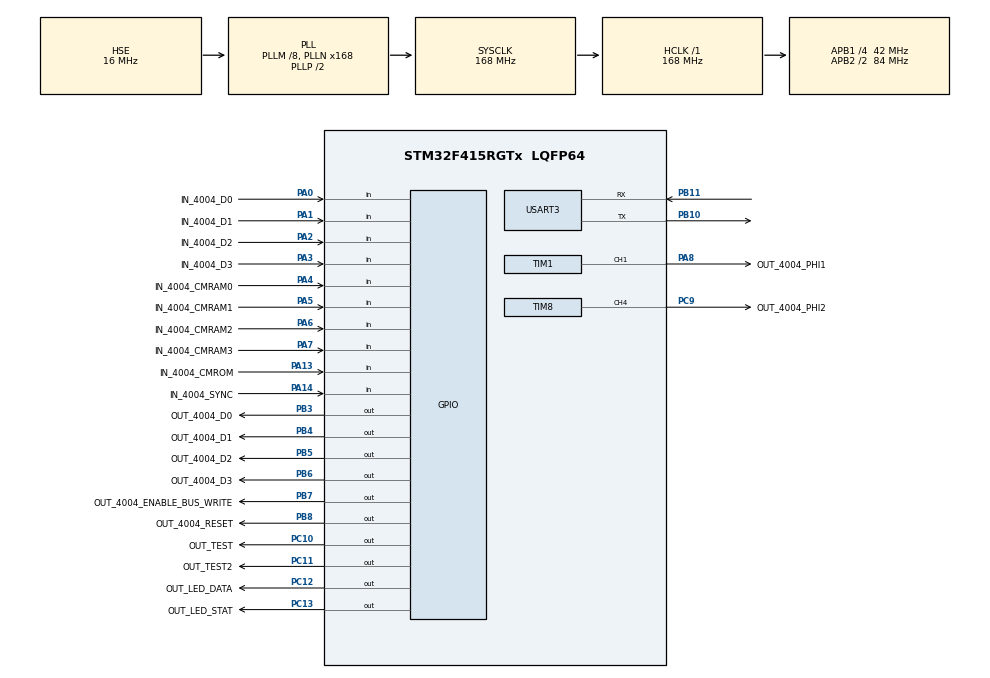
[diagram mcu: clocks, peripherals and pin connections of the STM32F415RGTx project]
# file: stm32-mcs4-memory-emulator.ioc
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Mcu.Family=STM32F4
Mcu.Name=STM32F415RGTx
Mcu.Package=LQFP64
NVIC.PriorityGroup=NVIC_PRIORITYGROUP_4
NVIC.TIM1_CC_IRQn=true\:0\:0\:false\:false\:true\:true\:true
NVIC.TIM8_CC_IRQn=true\:0\:0\:false\:false\:true\:true\:true
NVIC.USART3_IRQn=true\:0\:0\:false\:false\:true\:true\:true
PA0-WKUP.GPIO_Label=IN_4004_D0
PA0-WKUP.Signal=GPIO_Input
PA1.GPIO_Label=IN_4004_D1
PA1.Signal=GPIO_Input
PA13.GPIO_Label=IN_4004_CMROM
PA13.Signal=GPIO_Input
PA14.GPIO_Label=IN_4004_SYNC
PA14.Signal=GPIO_Input
PA2.GPIO_Label=IN_4004_D2
PA2.Signal=GPIO_Input
PA3.GPIO_Label=IN_4004_D3
PA3.Signal=GPIO_Input
PA4.GPIO_Label=IN_4004_CMRAM0
PA4.Signal=GPIO_Input
PA5.GPIO_Label=IN_4004_CMRAM1
PA5.Signal=GPIO_Input
PA6.GPIO_Label=IN_4004_CMRAM2
PA6.Signal=GPIO_Input
PA7.GPIO_Label=IN_4004_CMRAM3
PA7.Signal=GPIO_Input
PA8.GPIO_Label=OUT_4004_PHI1
PA8.Signal=S_TIM1_CH1
PB10.Mode=Asynchronous
PB10.Signal=USART3_TX
PB11.Mode=Asynchronous
PB11.Signal=USART3_RX
PB13.Signal=USART3_CTS
PB14.Signal=USART3_RTS
PB3.GPIO_Label=OUT_4004_D0
PB3.GPIO_Speed=GPIO_SPEED_FREQ_VERY_HIGH
PB3.Signal=GPIO_Output
PB4.GPIO_Label=OUT_4004_D1
PB4.GPIO_Speed=GPIO_SPEED_FREQ_VERY_HIGH
PB4.Signal=GPIO_Output
PB5.GPIO_Label=OUT_4004_D2
PB5.GPIO_Speed=GPIO_SPEED_FREQ_VERY_HIGH
PB5.Signal=GPIO_Output
PB6.GPIO_Label=OUT_4004_D3
PB6.GPIO_Speed=GPIO_SPEED_FREQ_VERY_HIGH
PB6.Signal=GPIO_Output
PB7.GPIO_Label=OUT_4004_ENABLE_BUS_WRITE
PB7.GPIO_Speed=GPIO_SPEED_FREQ_VERY_HIGH
PB7.Signal=GPIO_Output
PB8.GPIO_Label=OUT_4004_RESET
PB8.Signal=GPIO_Output
PC10.GPIO_Label=OUT_TEST
PC10.GPIO_Speed=GPIO_SPEED_FREQ_VERY_HIGH
PC10.Signal=GPIO_Output
PC11.GPIO_Label=OUT_TEST2
PC11.GPIO_Speed=GPIO_SPEED_FREQ_VERY_HIGH
PC11.Signal=GPIO_Output
PC12.GPIO_Label=OUT_LED_DATA
PC12.Signal=GPIO_Output
PC13-ANTI_TAMP.GPIO_Label=OUT_LED_STAT
PC13-ANTI_TAMP.Signal=GPIO_Output
PC9.GPIO_Label=OUT_4004_PHI2
PC9.Signal=S_TIM8_CH4
PH0-OSC_IN.Mode=HSE-External-Oscillator
PH0-OSC_IN.Signal=RCC_OSC_IN
PH1-OSC_OUT.Mode=HSE-External-Oscillator
PH1-OSC_OUT.Signal=RCC_OSC_OUT
ProjectManager.HeapSize=0x200
ProjectManager.StackSize=0x400
ProjectManager.TargetToolchain=SW4STM32
RCC.48MHZClocksFreq_Value=48000000
RCC.AHBFreq_Value=168000000
RCC.APB1CLKDivider=RCC_HCLK_DIV4
RCC.APB1Freq_Value=42000000
RCC.APB1TimFreq_Value=84000000
RCC.APB2CLKDivider=RCC_HCLK_DIV2
RCC.APB2Freq_Value=84000000
RCC.APB2TimFreq_Value=168000000
RCC.CortexFreq_Value=168000000
RCC.HCLKFreq_Value=168000000
RCC.HSE_VALUE=16000000
RCC.HSI_VALUE=16000000
RCC.LSE_VALUE=32768
RCC.PLLM=8
RCC.PLLN=168
RCC.PLLQ=7
RCC.PLLSourceVirtual=RCC_PLLSOURCE_HSE
RCC.SYSCLKFreq_VALUE=168000000
RCC.SYSCLKSource=RCC_SYSCLKSOURCE_PLLCLK
RCC.VCOOutputFreq_Value=336000000
SH.S_TIM1_CH1.0=TIM1_CH1,PWM Generation1 CH1
SH.S_TIM8_CH4.0=TIM8_CH4,PWM Generation4 CH4
TIM1.Channel-Output\ Compare2\ No\ Output=TIM_CHANNEL_2
TIM1.Channel-PWM\ Generation1\ CH1=TIM_CHANNEL_1
TIM1.OCMode_2=TIM_OCMODE_ACTIVE
TIM1.Period=268
TIM1.Pulse-Output\ Compare2\ No\ Output=133
TIM1.Pulse-PWM\ Generation1\ CH1=197
TIM1.TIM_MasterOutputTrigger=TIM_TRGO_OC2REF
TIM1.TIM_MasterSlaveMode=TIM_MASTERSLAVEMODE_ENABLE
TIM8.Channel-PWM\ Generation4\ CH4=TIM_CHANNEL_4
TIM8.Period=268
TIM8.Pulse-PWM\ Generation4\ CH4=197
TIM8.TIM_MasterOutputTrigger=TIM_TRGO_RESET
TIM8.TIM_MasterSlaveMode=TIM_MASTERSLAVEMODE_DISABLE
USART3.VirtualMode=VM_ASYNC
VP_TIM1_VS_ClockSourceINT.Mode=Internal
VP_TIM1_VS_no_output2.Mode=Output Compare2 No Output
VP_TIM8_VS_ClockSourceINT.Mode=Internal
VP_TIM8_VS_ClockSourceITR.Mode=TriggerSource_ITR0
VP_TIM8_VS_ControllerModeReset.Mode=Reset Mode
board=custom

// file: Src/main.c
/* USER CODE BEGIN Header */
/**
  ******************************************************************************
  * @file           : main.c
  * @brief          : Main program body
  ******************************************************************************
  * @attention
  *
  * <h2><center>&copy; Copyright (c) 2020 STMicroelectronics.
  * All rights reserved.</center></h2>
  *
  * This software component is licensed by ST under Ultimate Liberty license
  * SLA0044, the "License"; You may not use this file except in compliance with
  * the License. You may obtain a copy of the License at:
  *                             www.st.com/SLA0044
  *
  ******************************************************************************
  */
/* USER CODE END Header */

#include "main.h"
#include "tim.h"
#include "usart.h"
#include "gpio.h"

/* USER CODE BEGIN Includes */
#include "loop.h"
#include "init.h"
/* USER CODE END Includes */

void SystemClock_Config(void);

int main(void)
{
  /* USER CODE BEGIN 1 */
  // Boot-loader can set PLL as system clock source, but we need to configure PLL coefs, so temporary switches to HSI
  if (__HAL_RCC_GET_SYSCLK_SOURCE() == RCC_CFGR_SWS_PLL) {
    RCC->CFGR = (RCC->CFGR & ~(RCC_CFGR_SW)) | RCC_CFGR_SW_HSI;
  }
  /* USER CODE END 1 */

  /* MCU Configuration--------------------------------------------------------*/

  /* Reset of all peripherals, Initializes the Flash interface and the Systick. */
  HAL_Init();

  /* Configure the system clock */
  SystemClock_Config();

  /* Initialize all configured peripherals */
  MX_GPIO_Init();
  MX_TIM1_Init();
  MX_TIM8_Init();
  MX_USART3_UART_Init();
  /* USER CODE BEGIN 2 */
  init();
  /* USER CODE END 2 */

  /* Infinite loop */
  while (1)
  {

    /* USER CODE BEGIN 3 */
    loopTick();
  }
  /* USER CODE END 3 */
}

void SystemClock_Config(void)
{
  RCC_OscInitTypeDef RCC_OscInitStruct = {0};
  RCC_ClkInitTypeDef RCC_ClkInitStruct = {0};

  /** Configure the main internal regulator output voltage
  */
  __HAL_RCC_PWR_CLK_ENABLE();
  __HAL_PWR_VOLTAGESCALING_CONFIG(PWR_REGULATOR_VOLTAGE_SCALE1);
  /** Initializes the CPU, AHB and APB busses clocks
  */
  RCC_OscInitStruct.OscillatorType = RCC_OSCILLATORTYPE_HSE;
  RCC_OscInitStruct.HSEState = RCC_HSE_ON;
  RCC_OscInitStruct.PLL.PLLState = RCC_PLL_ON;
  RCC_OscInitStruct.PLL.PLLSource = RCC_PLLSOURCE_HSE;
  RCC_OscInitStruct.PLL.PLLM = 8;
  RCC_OscInitStruct.PLL.PLLN = 168;
  RCC_OscInitStruct.PLL.PLLP = RCC_PLLP_DIV2;
  RCC_OscInitStruct.PLL.PLLQ = 7;
  if (HAL_RCC_OscConfig(&RCC_OscInitStruct) != HAL_OK)
  {
    Error_Handler();
  }
  /** Initializes the CPU, AHB and APB busses clocks
  */
  RCC_ClkInitStruct.ClockType = RCC_CLOCKTYPE_HCLK|RCC_CLOCKTYPE_SYSCLK
                              |RCC_CLOCKTYPE_PCLK1|RCC_CLOCKTYPE_PCLK2;
  RCC_ClkInitStruct.SYSCLKSource = RCC_SYSCLKSOURCE_PLLCLK;
  RCC_ClkInitStruct.AHBCLKDivider = RCC_SYSCLK_DIV1;
  RCC_ClkInitStruct.APB1CLKDivider = RCC_HCLK_DIV4;
  RCC_ClkInitStruct.APB2CLKDivider = RCC_HCLK_DIV2;

  if (HAL_RCC_ClockConfig(&RCC_ClkInitStruct, FLASH_LATENCY_5) != HAL_OK)
  {
    Error_Handler();
  }
}

void Error_Handler(void)
{
  /* USER CODE BEGIN Error_Handler_Debug */
  /* User can add his own implementation to report the HAL error return state */
  HAL_GPIO_WritePin(GPIOC, GPIO_PIN_13, GPIO_PIN_SET);
  /* USER CODE END Error_Handler_Debug */
}

/************************ (C) COPYRIGHT STMicroelectronics *****END OF FILE****/
